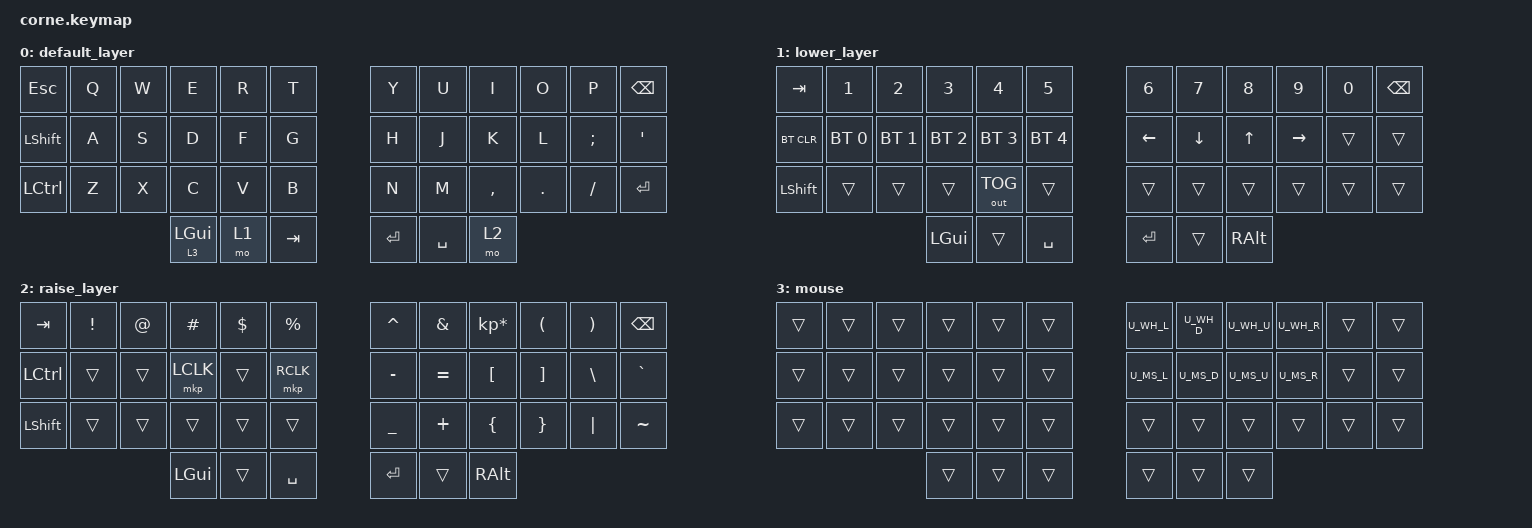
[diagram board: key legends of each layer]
/*
 * Copyright (c) 2020 The ZMK Contributors
 *
 * SPDX-License-Identifier: MIT
 */

#include <behaviors.dtsi>
#include <dt-bindings/zmk/bt.h>
#include <dt-bindings/zmk/keys.h>
#include <dt-bindings/zmk/outputs.h>


#include "mouse.dtsi"

/ {
    keymap {
        compatible = "zmk,keymap";

        default_layer {
            // -----------------------------------------------------------------------------------------
            // |  TAB |  Q  |  W  |  E  |  R  |  T  |   |  Y  |  U   |  I  |  O  |  P  | BKSP |
            // | CTRL |  A  |  S  |  D  |  F  |  G  |   |  H  |  J   |  K  |  L  |  ;  |  '   |
            // | SHFT |  Z  |  X  |  C  |  V  |  B  |   |  N  |  M   |  ,  |  .  |  /  | ESC  |
            //                    | GUI | LWR | SPC |   | ENT | RSE  | ALT |

            bindings = <
&kp ESC    &kp Q  &kp W  &kp E           &kp R  &kp T      &kp Y    &kp U      &kp I      &kp O    &kp P     &kp BSPC
&kp LSHFT  &kp A  &kp S  &kp D           &kp F  &kp G      &kp H    &kp J      &kp K      &kp L    &kp SEMI  &kp SQT
&kp LCTRL  &kp Z  &kp X  &kp C           &kp V  &kp B      &kp N    &kp M      &kp COMMA  &kp DOT  &kp FSLH  &kp RET
                         &lt 3 LEFT_GUI  &mo 1  &kp TAB    &kp RET  &kp SPACE  &mo 2
            >;
        };

        lower_layer {
            // -----------------------------------------------------------------------------------------
            // |  TAB |  1  |  2  |  3  |  4  |  5  |   |  6  |  7  |  8  |  9  |  0  | BKSP |
            // | BTCLR| BT1 | BT2 | BT3 | BT4 | BT5 |   | LFT | DWN |  UP | RGT |     |      |
            // | SHFT |     |     |     |     |     |   |     |     |     |     |     |      |
            //                    | GUI |     | SPC |   | ENT |     | ALT |

            bindings = <
&kp TAB     &kp N1        &kp N2        &kp N3        &kp N4        &kp N5          &kp N6    &kp N7    &kp N8    &kp N9     &kp N0  &kp BSPC
&bt BT_CLR  &bt BT_SEL 0  &bt BT_SEL 1  &bt BT_SEL 2  &bt BT_SEL 3  &bt BT_SEL 4    &kp LEFT  &kp DOWN  &kp UP    &kp RIGHT  &trans  &trans
&kp LSHFT   &trans        &trans        &trans        &out OUT_TOG  &trans          &trans    &trans    &trans    &trans     &trans  &trans
                                        &kp LGUI      &trans        &kp SPACE       &kp RET   &trans    &kp RALT
            >;
        };

        raise_layer {
            // -----------------------------------------------------------------------------------------
            // |  TAB |  !  |  @  |  #  |  $  |  %  |   |  ^  |  &  |  *  |  (  |  )  | BKSP |
            // | CTRL |     |     |     |     |     |   |  -  |  =  |  [  |  ]  |  \  |  `   |
            // | SHFT |     |     |     |     |     |   |  _  |  +  |  {  |  }  | "|" |  ~   |
            //                    | GUI |     | SPC |   | ENT |     | ALT |

            bindings = <
&kp TAB    &kp EXCL  &kp AT  &kp HASH   &kp DLLR  &kp PRCNT    &kp CARET  &kp AMPS   &kp KP_MULTIPLY  &kp LPAR  &kp RPAR  &kp BSPC
&kp LCTRL  &trans    &trans  &mkp LCLK  &trans    &mkp RCLK    &kp MINUS  &kp EQUAL  &kp LBKT         &kp RBKT  &kp BSLH  &kp GRAVE
&kp LSHFT  &trans    &trans  &trans     &trans    &trans       &kp UNDER  &kp PLUS   &kp LBRC         &kp RBRC  &kp PIPE  &kp TILDE
                             &kp LGUI   &trans    &kp SPACE    &kp RET    &trans     &kp RALT
            >;
        };

        mouse {
            bindings = <
&trans  &trans  &trans  &trans  &trans  &trans    U_WH_L  U_WH_D  U_WH_U  U_WH_R  &trans  &trans
&trans  &trans  &trans  &trans  &trans  &trans    U_MS_L  U_MS_D  U_MS_U  U_MS_R  &trans  &trans
&trans  &trans  &trans  &trans  &trans  &trans    &trans  &trans  &trans  &trans  &trans  &trans
                        &trans  &trans  &trans    &trans  &trans  &trans
            >;
        };
    };
};
